AUTOSAR XML (schema 314)
package /ComponentType
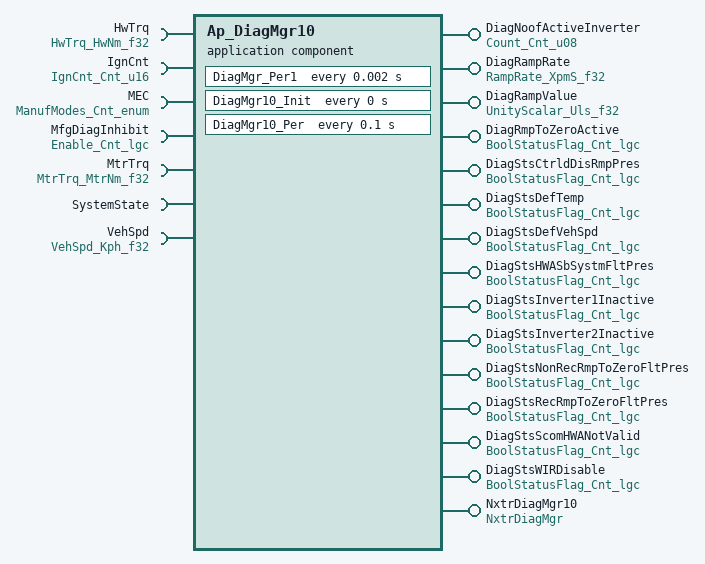
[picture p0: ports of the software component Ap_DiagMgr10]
  application software component type Ap_DiagMgr10
    15 x provide port:
      DiagNoofActiveInverter: unqueued-sender-com-spec{data-element=Cnt_u08, can-invalidate=false, init-value=D_TWO_CNT_U08}, provided-interface=Count_Cnt_u08
      DiagRampRate: unqueued-sender-com-spec{data-element=XpmS_f32, can-invalidate=false, init-value=D_ZERO_ULS_F32}, provided-interface=RampRate_XpmS_f32
      DiagRampValue: unqueued-sender-com-spec{data-element=Uls_f32, can-invalidate=false, init-value=D_ZERO_ULS_F32}, provided-interface=UnityScalar_Uls_f32
      DiagRmpToZeroActive: unqueued-sender-com-spec{data-element=Cnt_lgc, can-invalidate=false, init-value=D_FALSE_CNT_LGC}, provided-interface=BoolStatusFlag_Cnt_lgc
      DiagStsCtrldDisRmpPres: unqueued-sender-com-spec{data-element=Cnt_lgc, can-invalidate=false, init-value=D_FALSE_CNT_LGC}, provided-interface=BoolStatusFlag_Cnt_lgc
      DiagStsDefTemp: unqueued-sender-com-spec{data-element=Cnt_lgc, can-invalidate=false, init-value=D_FALSE_CNT_LGC}, provided-interface=BoolStatusFlag_Cnt_lgc
      DiagStsDefVehSpd: unqueued-sender-com-spec{data-element=Cnt_lgc, can-invalidate=false, init-value=D_FALSE_CNT_LGC}, provided-interface=BoolStatusFlag_Cnt_lgc
      DiagStsHWASbSystmFltPres: unqueued-sender-com-spec{data-element=Cnt_lgc, can-invalidate=false, init-value=D_FALSE_CNT_LGC}, provided-interface=BoolStatusFlag_Cnt_lgc
      DiagStsInverter1Inactive: unqueued-sender-com-spec{data-element=Cnt_lgc, can-invalidate=false, init-value=D_FALSE_CNT_LGC}, provided-interface=BoolStatusFlag_Cnt_lgc
      DiagStsInverter2Inactive: unqueued-sender-com-spec{data-element=Cnt_lgc, can-invalidate=false, init-value=D_FALSE_CNT_LGC}, provided-interface=BoolStatusFlag_Cnt_lgc
      DiagStsNonRecRmpToZeroFltPres: unqueued-sender-com-spec{data-element=Cnt_lgc, can-invalidate=false, init-value=D_FALSE_CNT_LGC}, provided-interface=BoolStatusFlag_Cnt_lgc
      DiagStsRecRmpToZeroFltPres: unqueued-sender-com-spec{data-element=Cnt_lgc, can-invalidate=false, init-value=D_FALSE_CNT_LGC}, provided-interface=BoolStatusFlag_Cnt_lgc
      DiagStsScomHWANotValid: unqueued-sender-com-spec{data-element=Cnt_lgc, can-invalidate=false, init-value=D_FALSE_CNT_LGC}, provided-interface=BoolStatusFlag_Cnt_lgc
      DiagStsWIRDisable: unqueued-sender-com-spec{data-element=Cnt_lgc, can-invalidate=false, init-value=D_FALSE_CNT_LGC}, provided-interface=BoolStatusFlag_Cnt_lgc
      NxtrDiagMgr10: provided-interface=NxtrDiagMgr
        provided-com-specs:
          operation=GetNTCActive, queue-length=1
          operation=GetNTCFailed, queue-length=1
          operation=GetNTCStatus, queue-length=1
          operation=SetNTCStatus, queue-length=1
    7 x require port:
      HwTrq: unqueued-receiver-com-spec{data-element=HwNm_f32, init-value=D_ZERO_ULS_F32}, required-interface=HwTrq_HwNm_f32
      IgnCnt: unqueued-receiver-com-spec{data-element=Cnt_u16, init-value=D_ZERO_CNT_U16}, required-interface=IgnCnt_Cnt_u16
      MEC: unqueued-receiver-com-spec{data-element=Cnt_enum, init-value=D_MANUFMODEINIT_CNT_ENUM}, required-interface=ManufModes_Cnt_enum
      MfgDiagInhibit: unqueued-receiver-com-spec{data-element=Cnt_lgc, init-value=D_FALSE_CNT_LGC}, required-interface=Enable_Cnt_lgc
      MtrTrq: unqueued-receiver-com-spec{data-element=MtrNm_f32, init-value=D_ZERO_ULS_F32}, required-interface=MtrTrq_MtrNm_f32
      SystemState: required-interface=SystemState
      VehSpd: unqueued-receiver-com-spec{data-element=Kph_f32, init-value=D_ZERO_ULS_F32}, required-interface=VehSpd_Kph_f32
  internal behavior Ap_DiagMgr10_InternalBehavior: component=Ap_DiagMgr10
    timing event TMT_DiagMgr_Per1: start-on-event=DiagMgr_Per1, period=0.002
    timing event DiagMgr10_InitEvent: start-on-event=DiagMgr10_Init, period=0
    timing event TMT_DiagMgr10_Per: start-on-event=DiagMgr10_Per, period=0.1
    mode switch event MST_DiagMgr10_Trns_0: start-on-event=DiagMgr10_Trns, activation=EXIT, mode=SystemState.Mode.OFF
    4 x operation invoked event:
      OIT_NxtrDiagMgr10_GetNTCActive_NxtrDiagMgr10_GetNTCActive: start-on-event=NxtrDiagMgr10_GetNTCActive, operation=NxtrDiagMgr10.GetNTCActive
      OIT_NxtrDiagMgr10_GetNTCFailed_NxtrDiagMgr10_GetNTCFailed: start-on-event=NxtrDiagMgr10_GetNTCFailed, operation=NxtrDiagMgr10.GetNTCFailed
      OIT_NxtrDiagMgr10_GetNTCStatus_NxtrDiagMgr10_GetNTCStatus: start-on-event=NxtrDiagMgr10_GetNTCStatus, operation=NxtrDiagMgr10.GetNTCStatus
      OIT_NxtrDiagMgr10_SetNTCStatus_NxtrDiagMgr10_SetNTCStatus: start-on-event=NxtrDiagMgr10_SetNTCStatus, operation=NxtrDiagMgr10.SetNTCStatus
    port-api-options:
      enable-take-address=false, indirect-api=false, port=DiagNoofActiveInverter
      enable-take-address=false, indirect-api=false, port=DiagRampRate
      enable-take-address=false, indirect-api=false, port=DiagRampValue
      enable-take-address=false, indirect-api=false, port=DiagRmpToZeroActive
      enable-take-address=false, indirect-api=false, port=DiagStsCtrldDisRmpPres
      enable-take-address=false, indirect-api=false, port=DiagStsDefTemp
      enable-take-address=false, indirect-api=false, port=DiagStsDefVehSpd
      enable-take-address=false, indirect-api=false, port=DiagStsHWASbSystmFltPres
      enable-take-address=false, indirect-api=false, port=DiagStsInverter1Inactive
      enable-take-address=false, indirect-api=false, port=DiagStsInverter2Inactive
      enable-take-address=false, indirect-api=false, port=DiagStsNonRecRmpToZeroFltPres
      enable-take-address=false, indirect-api=false, port=DiagStsRecRmpToZeroFltPres
      enable-take-address=false, indirect-api=false, port=DiagStsScomHWANotValid
      enable-take-address=false, indirect-api=false, port=DiagStsWIRDisable
      enable-take-address=false, indirect-api=false, port=HwTrq
      enable-take-address=false, indirect-api=false, port=IgnCnt
      enable-take-address=false, indirect-api=false, port=MEC
      enable-take-address=false, indirect-api=false, port=MfgDiagInhibit
      enable-take-address=false, indirect-api=false, port=MtrTrq
      enable-take-address=false, indirect-api=false, port=NxtrDiagMgr10
      enable-take-address=false, indirect-api=false, port=SystemState
      enable-take-address=false, indirect-api=false, port=VehSpd
    8 x runnable:
      DiagMgr_Per1
        14 x data send point:
          SEND_DiagNoofActiveInverter_Cnt_u08: data-element=DiagNoofActiveInverter.Cnt_u08
          SEND_DiagRampRate_XpmS_f32: data-element=DiagRampRate.XpmS_f32
          SEND_DiagRampValue_Uls_f32: data-element=DiagRampValue.Uls_f32
          SEND_DiagRmpToZeroActive_Cnt_lgc: data-element=DiagRmpToZeroActive.Cnt_lgc
          SEND_DiagStsCtrldDisRmpPres_Cnt_lgc: data-element=DiagStsCtrldDisRmpPres.Cnt_lgc
          SEND_DiagStsDefTemp_Cnt_lgc: data-element=DiagStsDefTemp.Cnt_lgc
          SEND_DiagStsDefVehSpd_Cnt_lgc: data-element=DiagStsDefVehSpd.Cnt_lgc
          SEND_DiagStsHWASbSystmFltPres_Cnt_lgc: data-element=DiagStsHWASbSystmFltPres.Cnt_lgc
          SEND_DiagStsInverter1Inactive_Cnt_lgc: data-element=DiagStsInverter1Inactive.Cnt_lgc
          SEND_DiagStsInverter2Inactive_Cnt_lgc: data-element=DiagStsInverter2Inactive.Cnt_lgc
          SEND_DiagStsNonRecRmpToZeroFltPres_Cnt_lgc: data-element=DiagStsNonRecRmpToZeroFltPres.Cnt_lgc
          SEND_DiagStsRecRmpToZeroFltPres_Cnt_lgc: data-element=DiagStsRecRmpToZeroFltPres.Cnt_lgc
          SEND_DiagStsScomHWANotValid_Cnt_lgc: data-element=DiagStsScomHWANotValid.Cnt_lgc
          SEND_DiagStsWIRDisable_Cnt_lgc: data-element=DiagStsWIRDisable.Cnt_lgc
      DiagMgr10_Init
      DiagMgr10_Per
      DiagMgr10_Trns
      NxtrDiagMgr10_GetNTCActive: can-be-invoked-concurrently=true
      NxtrDiagMgr10_GetNTCFailed: can-be-invoked-concurrently=true
      NxtrDiagMgr10_GetNTCStatus: can-be-invoked-concurrently=true
      NxtrDiagMgr10_SetNTCStatus: can-be-invoked-concurrently=true
        6 x data receive point:
          REC_HwTrq_HwNm_f32: data-element=HwTrq.HwNm_f32
          REC_IgnCnt_Cnt_u16: data-element=IgnCnt.Cnt_u16
          REC_MEC_Cnt_enum: data-element=MEC.Cnt_enum
          REC_MfgDiagInhibit_Cnt_lgc: data-element=MfgDiagInhibit.Cnt_lgc
          REC_MtrTrq_MtrNm_f32: data-element=MtrTrq.MtrNm_f32
          REC_VehSpd_Kph_f32: data-element=VehSpd.Kph_f32
  swc implementation Ap_DiagMgr10_Implementation: behavior=Ap_DiagMgr10_InternalBehavior
    code-descriptors:
      code Code: type=SRC
